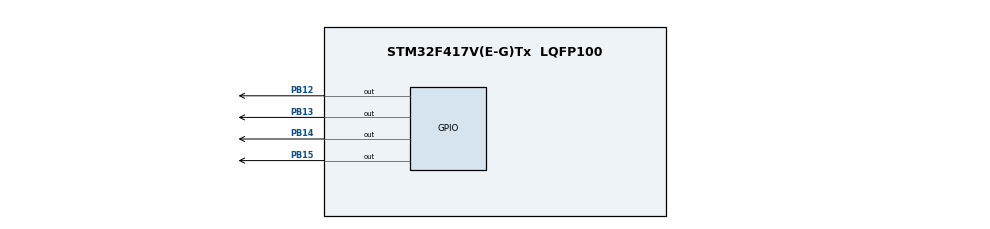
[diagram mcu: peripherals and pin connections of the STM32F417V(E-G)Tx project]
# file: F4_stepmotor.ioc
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Mcu.Family=STM32F4
Mcu.Name=STM32F417V(E-G)Tx
Mcu.Package=LQFP100
NVIC.PriorityGroup=NVIC_PRIORITYGROUP_4
NVIC.TIM6_DAC_IRQn=true\:0\:0\:false
PB12.Signal=GPIO_Output
PB13.Signal=GPIO_Output
PB14.Signal=GPIO_Output
PB15.Signal=GPIO_Output
ProjectManager.TargetToolchain=MDK-ARM V5
RCC.AHBFreq_Value=16000000
RCC.APB1Freq_Value=16000000
RCC.APB2Freq_Value=16000000
RCC.CortexFreq_Value=16000000
RCC.HSE_VALUE=25000000
RCC.HSI_VALUE=16000000
RCC.LSE_VALUE=32768
RCC.SYSCLKFreq_VALUE=16000000
RCC.VCOOutputFreq_Value=192000000
TIM6.Period=1000
TIM6.Prescaler=8000-1
VP_TIM6_VS_ClockSourceINT.Mode=Enable_Timer
board=F4_stepmotor

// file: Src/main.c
/**
  ******************************************************************************
  * File Name          : main.c
  * Description        : Main program body
  ******************************************************************************
  *
  * COPYRIGHT(c) 2015 STMicroelectronics
  *
  * Redistribution and use in source and binary forms, with or without modification,
  * are permitted provided that the following conditions are met:
  *   1. Redistributions of source code must retain the above copyright notice,
  *      this list of conditions and the following disclaimer.
  *   2. Redistributions in binary form must reproduce the above copyright notice,
  *      this list of conditions and the following disclaimer in the documentation
  *      and/or other materials provided with the distribution.
  *   3. Neither the name of STMicroelectronics nor the names of its contributors
  *      may be used to endorse or promote products derived from this software
  *      without specific prior written permission.
  *
  * THIS SOFTWARE IS PROVIDED BY THE COPYRIGHT HOLDERS AND CONTRIBUTORS "AS IS"
  * AND ANY EXPRESS OR IMPLIED WARRANTIES, INCLUDING, BUT NOT LIMITED TO, THE
  * IMPLIED WARRANTIES OF MERCHANTABILITY AND FITNESS FOR A PARTICULAR PURPOSE ARE
  * DISCLAIMED. IN NO EVENT SHALL THE COPYRIGHT HOLDER OR CONTRIBUTORS BE LIABLE
  * FOR ANY DIRECT, INDIRECT, INCIDENTAL, SPECIAL, EXEMPLARY, OR CONSEQUENTIAL
  * DAMAGES (INCLUDING, BUT NOT LIMITED TO, PROCUREMENT OF SUBSTITUTE GOODS OR
  * SERVICES; LOSS OF USE, DATA, OR PROFITS; OR BUSINESS INTERRUPTION) HOWEVER
  * CAUSED AND ON ANY THEORY OF LIABILITY, WHETHER IN CONTRACT, STRICT LIABILITY,
  * OR TORT (INCLUDING NEGLIGENCE OR OTHERWISE) ARISING IN ANY WAY OUT OF THE USE
  * OF THIS SOFTWARE, EVEN IF ADVISED OF THE POSSIBILITY OF SUCH DAMAGE.
  *
  ******************************************************************************
  */
#include "stm32f4xx_hal.h"
#include "tim.h"
#include "gpio.h"

/* USER CODE BEGIN PV */
/* Private variables ---------------------------------------------------------*/

/* USER CODE END PV */

void SystemClock_Config(void);

/* USER CODE BEGIN PFP */
/* Private function prototypes -----------------------------------------------*/

/* USER CODE END PFP */

int main(void)
{

  /* MCU Configuration----------------------------------------------------------*/

  /* Reset of all peripherals, Initializes the Flash interface and the Systick. */
  HAL_Init();

  /* Configure the system clock */
  SystemClock_Config();

  /* Initialize all configured peripherals */
  MX_GPIO_Init();
  MX_TIM6_Init();

  /* USER CODE BEGIN 2 */
  HAL_TIM_Base_Start_IT(&htim6);
  /* USER CODE END 2 */

  /* Infinite loop */
  while (1)
  {

  /* USER CODE BEGIN 3 */
		/*
	HAL_GPIO_WritePin(GPIOB, GPIO_PIN_12 , 1);
	HAL_GPIO_WritePin(GPIOB, GPIO_PIN_13 , 1);
	HAL_GPIO_WritePin(GPIOB, GPIO_PIN_14 , 1);
	HAL_GPIO_WritePin(GPIOB, GPIO_PIN_15 , 1);
	for(int i=0; i<1000000; i++);
	HAL_GPIO_WritePin(GPIOB, GPIO_PIN_12 , 0);
	HAL_GPIO_WritePin(GPIOB, GPIO_PIN_13 , 0);
	HAL_GPIO_WritePin(GPIOB, GPIO_PIN_14 , 0);
	HAL_GPIO_WritePin(GPIOB, GPIO_PIN_15 , 0);
	for(int i=0; i<1000000; i++);
		*/

  }
  /* USER CODE END 3 */

}

/** System Clock Configuration
*/
void SystemClock_Config(void)
{

  RCC_OscInitTypeDef RCC_OscInitStruct;

  __PWR_CLK_ENABLE();

  __HAL_PWR_VOLTAGESCALING_CONFIG(PWR_REGULATOR_VOLTAGE_SCALE1);

  RCC_OscInitStruct.OscillatorType = RCC_OSCILLATORTYPE_HSI;
  RCC_OscInitStruct.HSIState = RCC_HSI_ON;
  RCC_OscInitStruct.HSICalibrationValue = 16;
  RCC_OscInitStruct.PLL.PLLState = RCC_PLL_NONE;
  HAL_RCC_OscConfig(&RCC_OscInitStruct);

  HAL_SYSTICK_Config(HAL_RCC_GetHCLKFreq()/1000);

  HAL_SYSTICK_CLKSourceConfig(SYSTICK_CLKSOURCE_HCLK);

  /* SysTick_IRQn interrupt configuration */
  HAL_NVIC_SetPriority(SysTick_IRQn, 0, 0);
}

/************************ (C) COPYRIGHT STMicroelectronics *****END OF FILE****/
